# SAM9X75D1GN2 device description
Architecture: ARM926EJ-S; Family: SAM9; Series: SAM9X7
Registers are 32-bit, read-write, reset 0x0 unless marked. A register's access mark holds for its fields unless they carry their own. Offsets are from the block's base; [hi:lo] are bit positions.

## RTT — Real-time Timer
Instances: RTT 0xFFFFFE20
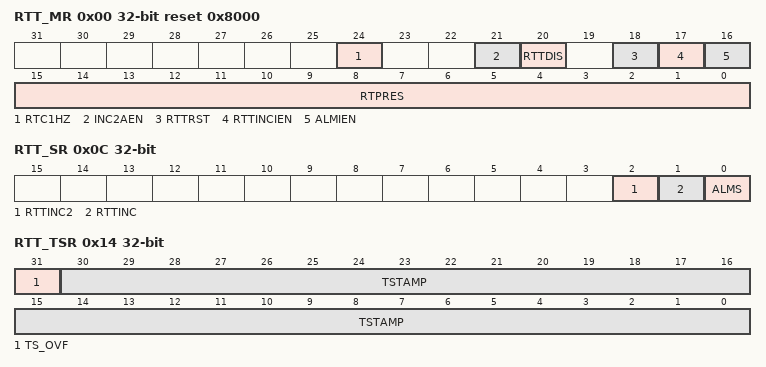
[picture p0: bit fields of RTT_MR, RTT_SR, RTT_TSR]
0x00 RTT_MR reset 0x8000 — Mode Register
  [24] RTC1HZ — Real-Time Clock 1Hz Clock Selection
    0=The RTT 32-bit counter is driven by the 16-bit prescaler roll-over events; 1=The RTT 32-bit counter is driven by the 1Hz RTC clock
  [21] INC2AEN — RTTINC2 Alarm and Interrupt Enable
    0=The RTTINC2 flag is not a source of the RTT alarm signal nor a source of interrupt; 1=The RTTINC2 flag is a source of the RTT alarm signal and a source of interrupt
  [20] RTTDIS — Real-Time Timer Disable
    0=The Real-Time Timer is enabled; 1=The Real-Time Timer is disabled (no dynamic power consumption)
  [18] RTTRST — Real-Time Timer Restart
    0=No effect; 1=Reloads and restarts the clock divider with the new programmed value. This also resets the 32-bit counter.
  [17] RTTINCIEN — Real-Time Timer Increment Interrupt Enable
    0=The RTT_SR.RTTINC bit has no effect on interrupt; 1=The RTT_SR.RTTINC bit asserts interrupt
  [16] ALMIEN — Alarm Interrupt Enable
    0=The RTT_SR.ALMS bit has no effect on interrupt; 1=The RTT_SR.ALMS bit asserts interrupt
  [15:0] RTPRES — Real-Time Timer Prescaler Value
0x04 RTT_AR reset 0xFFFFFFFF — Alarm Register
  [31:0] ALMV — Alarm Value
0x08 RTT_VR ro — Value Register
  [31:0] CRTV — Current Real-time Value
0x0C RTT_SR ro — Status Register
  [2] RTTINC2 — Predefined Number of Prescaler Roll-Over Status (cleared on read)
    0=SELINC2=0 or the number of prescaler roll-overs programmed through the SELINC2 field in RTT_MODR has not been reached since the last read of the RTT_SR; 1=The number of prescaler roll-overs programmed through the SELINC2 field has been reached since the last read of the RTT_SR
  [1] RTTINC — Prescaler Roll-over Status (cleared on read)
    0=No prescaler roll-over occurred since the last read of the RTT_SR; 1=Prescaler roll-over occurred since the last read of the RTT_SR
  [0] ALMS — Real-Time Alarm Status (cleared on read)
    0=The real-time zlarm has not occurred since the last read of RTT_SR; 1=The real-time alarm occurred since the last read of RTT_SR
0x10 RTT_MODR — Modulo Selection Register
  [2:0] SELINC2 — Selection of the 32-bit Counter Modulo to generate RTTINC2 Flag
    0=NO_RTTINC2 (The RTTINC2 flag never rises.); 1=MOD64 (The RTTINC2 flag is set when CRTV modulo 64 equals 0.); 2=MOD128 (The RTTINC2 flag is set when CRTV modulo 128 equals 0.); 3=MOD256 (The RTTINC2 flag is set when CRTV modulo 256 equals 0.); 4=MOD512 (The RTTINC2 flag is set when CRTV modulo 512 equals 0.); 5=MOD1024 (The RTTINC2 flag is set when CRTV modulo 1024 equals 0. Example: If RTPRES=32 then RTTINC2 flag rises once per second if the slow clock is 32.768 kHz.); 6=MOD2048 (The RTTINC2 flag is set when CRTV modulo 2048 equals 0.); 7=MOD4096 (The RTTINC2 flag is set when CRTV modulo 4096 equals 0.)
0x14 RTT_TSR ro — TimeStamp Register
  [31] TS_OVF — Timestamp Overflow
    0=RTT_ST.RTTINC2 was set but no new event occurred since the last read of RTT_SR; 1=RTT_ST.RTTINC2 was set and a second event occurred. To avoid any overflow, clear RTTINC2 by reading RTT_SR.
  [30:0] TSTAMP — Real-Time Timer Value Timestamp

## SCKC — Slow Clock Controller
Instances: SCKC 0xFFFFFE50
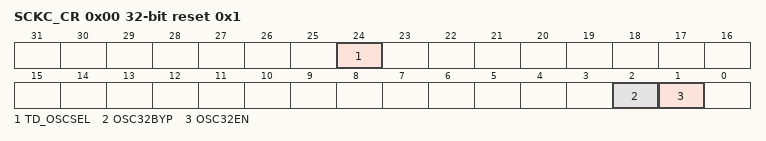
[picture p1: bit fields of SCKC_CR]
0x00 SCKC_CR reset 0x1 — Slow Clock Controller Configuration Register
  [24] TD_OSCSEL — Timing Domain Slow Clock Selector
    0=RC (Slow clock of the timing domain is driven by the embedded 32 kHz (typical) RC oscillator.); 1=XTAL (Slow clock of the timing domain is driven by the 32.768 kHz crystal oscillator.)
  [2] OSC32BYP — 32.768 kHz Crystal Oscillator Bypass
    0=32.768 kHz crystal oscillator is not bypassed; 1=32.768 kHz crystal oscillator is bypassed and accepts an external slow clock on XIN32
  [1] OSC32EN — 32.768 kHz Crystal Oscillator
    0=32.768 kHz crystal oscillator is disabled; 1=32.768 kHz crystal oscillator is enabled
